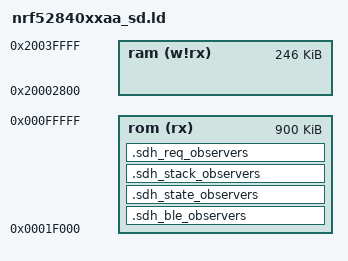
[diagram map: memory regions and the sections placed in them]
/*
 * Copyright (C) 2017 Freie Universität Berlin
 *
 * This file is subject to the terms and conditions of the GNU Lesser
 * General Public License v2.1. See the file LICENSE in the top level
 * directory for more details.
 */

/**
 * @addtogroup      cpu_nrf52
 * @{
 *
 * @file
 * @brief           Memory definitions for the NRF52840XXAA
 *
 * @author          Hauke Petersen <hauke.petersen@fu-berlin.de>
 *
 * @}
 */

MEMORY
{
    rom (rx)    : ORIGIN =    0x1f000, LENGTH = 0xe1000
    ram (w!rx)  : ORIGIN = 0x20002800, LENGTH = 0x3D800
}

SECTIONS
{
  .sdh_ble_observers :
  {
    PROVIDE(__start_sdh_ble_observers = .);
    KEEP(*(SORT(.sdh_ble_observers*)))
    PROVIDE(__stop_sdh_ble_observers = .);
  } > rom
   .sdh_state_observers :
  {
    PROVIDE(__start_sdh_state_observers = .);
    KEEP(*(SORT(.sdh_state_observers*)))
    PROVIDE(__stop_sdh_state_observers = .);
  } > rom
  .sdh_stack_observers :
  {
    PROVIDE(__start_sdh_stack_observers = .);
    KEEP(*(SORT(.sdh_stack_observers*)))
    PROVIDE(__stop_sdh_stack_observers = .);
  } > rom
  .sdh_req_observers :
  {
    PROVIDE(__start_sdh_req_observers = .);
    KEEP(*(SORT(.sdh_req_observers*)))
    PROVIDE(__stop_sdh_req_observers = .);
  } > rom

  __data_start__ = ORIGIN(ram);

} INSERT AFTER .text

INCLUDE cortexm_base.ld
